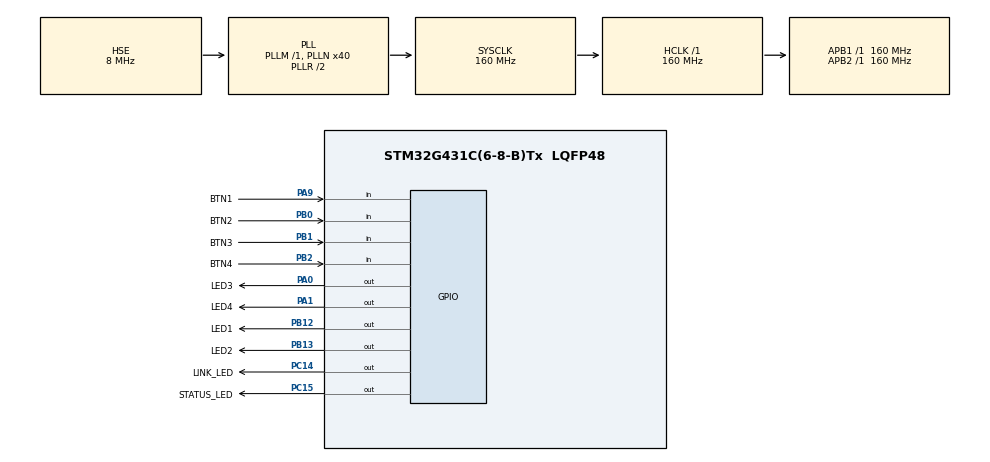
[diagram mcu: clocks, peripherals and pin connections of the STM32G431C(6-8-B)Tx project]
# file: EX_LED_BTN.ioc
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Mcu.Family=STM32G4
Mcu.Name=STM32G431C(6-8-B)Tx
Mcu.Package=LQFP48
NVIC.PriorityGroup=NVIC_PRIORITYGROUP_4
PA0.GPIO_Label=LED3
PA0.Signal=GPIO_Output
PA1.GPIO_Label=LED4
PA1.Signal=GPIO_Output
PA9.GPIO_Label=BTN1
PA9.GPIO_PuPd=GPIO_NOPULL
PA9.Signal=GPIO_Input
PB0.GPIO_Label=BTN2
PB0.GPIO_PuPd=GPIO_NOPULL
PB0.Signal=GPIO_Input
PB1.GPIO_Label=BTN3
PB1.GPIO_PuPd=GPIO_NOPULL
PB1.Signal=GPIO_Input
PB12.GPIO_Label=LED1
PB12.Signal=GPIO_Output
PB13.GPIO_Label=LED2
PB13.Signal=GPIO_Output
PB2.GPIO_Label=BTN4
PB2.GPIO_PuPd=GPIO_NOPULL
PB2.Signal=GPIO_Input
PC14-OSC32_IN.GPIO_Label=LINK_LED
PC14-OSC32_IN.Signal=GPIO_Output
PC15-OSC32_OUT.GPIO_Label=STATUS_LED
PC15-OSC32_OUT.Signal=GPIO_Output
PF0-OSC_IN.Mode=HSE-External-Oscillator
PF0-OSC_IN.Signal=RCC_OSC_IN
PF1-OSC_OUT.Mode=HSE-External-Oscillator
PF1-OSC_OUT.Signal=RCC_OSC_OUT
ProjectManager.HeapSize=0x200
ProjectManager.StackSize=0x400
ProjectManager.TargetToolchain=STM32CubeIDE
RCC.ADC12Freq_Value=160000000
RCC.AHBFreq_Value=160000000
RCC.APB1Freq_Value=160000000
RCC.APB1TimFreq_Value=160000000
RCC.APB2Freq_Value=160000000
RCC.APB2TimFreq_Value=160000000
RCC.CortexFreq_Value=160000000
RCC.EXTERNAL_CLOCK_VALUE=12288000
RCC.HCLKFreq_Value=160000000
RCC.HSE_VALUE=8000000
RCC.HSI48_VALUE=48000000
RCC.HSI_VALUE=16000000
RCC.LSE_VALUE=32768
RCC.PLLN=40
RCC.PLLSourceVirtual=RCC_PLLSOURCE_HSE
RCC.SYSCLKFreq_VALUE=160000000
RCC.SYSCLKSource=RCC_SYSCLKSOURCE_PLLCLK
RCC.USBFreq_Value=160000000
RCC.VCOOutputFreq_Value=320000000
VP_SYS_VS_DBSignals.Mode=DisableDeadBatterySignals
board=custom

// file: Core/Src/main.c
/* USER CODE BEGIN Header */
/**
  ******************************************************************************
  * @file           : main.c
  * @brief          : Main program body
  ******************************************************************************
  * @attention
  *
  * Copyright (c) 2025 STMicroelectronics.
  * All rights reserved.
  *
  * This software is licensed under terms that can be found in the LICENSE file
  * in the root directory of this software component.
  * If no LICENSE file comes with this software, it is provided AS-IS.
  *
  ******************************************************************************
  */
/* USER CODE END Header */
#include "main.h"

void SystemClock_Config(void);
static void MX_GPIO_Init(void);

/* USER CODE BEGIN 0 */

void ButtonLedTask(void)
{
  // 회로도를 참조하시면 해당 STATUS_LED_Pin 혹은  LINK_LED_Pin이 LOW로 떨어져야 LED 1,2가 켜집니다.
  // 버튼1 → LED1

  if (HAL_GPIO_ReadPin(BTN1_GPIO_Port, BTN1_Pin) == GPIO_PIN_RESET)
  {
	  HAL_GPIO_WritePin(STATUS_LED_GPIO_Port, STATUS_LED_Pin, GPIO_PIN_RESET);
  }
  else
  {
	  HAL_GPIO_WritePin(STATUS_LED_GPIO_Port, STATUS_LED_Pin, GPIO_PIN_SET);
  }

  // 버튼2 → LED2
  if (HAL_GPIO_ReadPin(BTN2_GPIO_Port, BTN2_Pin) == GPIO_PIN_RESET)
  {
	  HAL_GPIO_WritePin(LINK_LED_GPIO_Port, LINK_LED_Pin, GPIO_PIN_RESET);
  }
  else
  {
	  HAL_GPIO_WritePin(LINK_LED_GPIO_Port, LINK_LED_Pin, GPIO_PIN_SET);
  }

}

/* USER CODE END 0 */

int main(void)
{

  /* MCU Configuration--------------------------------------------------------*/

  /* Reset of all peripherals, Initializes the Flash interface and the Systick. */
  HAL_Init();

  /* Configure the system clock */
  SystemClock_Config();

  /* Initialize all configured peripherals */
  MX_GPIO_Init();

  /* Infinite loop */
  /* USER CODE BEGIN WHILE */
  while (1)
  {
	  // 버튼을 무한정 감시합니다!
	  ButtonLedTask();
    /* USER CODE END WHILE */

  }
}

void SystemClock_Config(void)
{
  RCC_OscInitTypeDef RCC_OscInitStruct = {0};
  RCC_ClkInitTypeDef RCC_ClkInitStruct = {0};

  /** Configure the main internal regulator output voltage
  */
  HAL_PWREx_ControlVoltageScaling(PWR_REGULATOR_VOLTAGE_SCALE1_BOOST);

  /** Initializes the RCC Oscillators according to the specified parameters
  * in the RCC_OscInitTypeDef structure.
  */
  RCC_OscInitStruct.OscillatorType = RCC_OSCILLATORTYPE_HSE;
  RCC_OscInitStruct.HSEState = RCC_HSE_ON;
  RCC_OscInitStruct.PLL.PLLState = RCC_PLL_ON;
  RCC_OscInitStruct.PLL.PLLSource = RCC_PLLSOURCE_HSE;
  RCC_OscInitStruct.PLL.PLLM = RCC_PLLM_DIV1;
  RCC_OscInitStruct.PLL.PLLN = 40;
  RCC_OscInitStruct.PLL.PLLP = RCC_PLLP_DIV2;
  RCC_OscInitStruct.PLL.PLLQ = RCC_PLLQ_DIV2;
  RCC_OscInitStruct.PLL.PLLR = RCC_PLLR_DIV2;
  if (HAL_RCC_OscConfig(&RCC_OscInitStruct) != HAL_OK)
  {
    Error_Handler();
  }

  /** Initializes the CPU, AHB and APB buses clocks
  */
  RCC_ClkInitStruct.ClockType = RCC_CLOCKTYPE_HCLK|RCC_CLOCKTYPE_SYSCLK
                              |RCC_CLOCKTYPE_PCLK1|RCC_CLOCKTYPE_PCLK2;
  RCC_ClkInitStruct.SYSCLKSource = RCC_SYSCLKSOURCE_PLLCLK;
  RCC_ClkInitStruct.AHBCLKDivider = RCC_SYSCLK_DIV1;
  RCC_ClkInitStruct.APB1CLKDivider = RCC_HCLK_DIV1;
  RCC_ClkInitStruct.APB2CLKDivider = RCC_HCLK_DIV1;

  if (HAL_RCC_ClockConfig(&RCC_ClkInitStruct, FLASH_LATENCY_4) != HAL_OK)
  {
    Error_Handler();
  }
}

static void MX_GPIO_Init(void)
{
  GPIO_InitTypeDef GPIO_InitStruct = {0};

  /* GPIO Ports Clock Enable */
  __HAL_RCC_GPIOC_CLK_ENABLE();
  __HAL_RCC_GPIOF_CLK_ENABLE();
  __HAL_RCC_GPIOA_CLK_ENABLE();
  __HAL_RCC_GPIOB_CLK_ENABLE();

  /*Configure GPIO pin Output Level */
  HAL_GPIO_WritePin(GPIOC, LINK_LED_Pin|STATUS_LED_Pin, GPIO_PIN_RESET);

  /*Configure GPIO pin Output Level */
  HAL_GPIO_WritePin(GPIOA, LED3_Pin|LED4_Pin, GPIO_PIN_RESET);

  /*Configure GPIO pin Output Level */
  HAL_GPIO_WritePin(GPIOB, LED1_Pin|LED2_Pin, GPIO_PIN_RESET);

  /*Configure GPIO pins : LINK_LED_Pin STATUS_LED_Pin */
  GPIO_InitStruct.Pin = LINK_LED_Pin|STATUS_LED_Pin;
  GPIO_InitStruct.Mode = GPIO_MODE_OUTPUT_PP;
  GPIO_InitStruct.Pull = GPIO_NOPULL;
  GPIO_InitStruct.Speed = GPIO_SPEED_FREQ_LOW;
  HAL_GPIO_Init(GPIOC, &GPIO_InitStruct);

  /*Configure GPIO pins : LED3_Pin LED4_Pin */
  GPIO_InitStruct.Pin = LED3_Pin|LED4_Pin;
  GPIO_InitStruct.Mode = GPIO_MODE_OUTPUT_PP;
  GPIO_InitStruct.Pull = GPIO_NOPULL;
  GPIO_InitStruct.Speed = GPIO_SPEED_FREQ_LOW;
  HAL_GPIO_Init(GPIOA, &GPIO_InitStruct);

  /*Configure GPIO pins : BTN2_Pin BTN3_Pin BTN4_Pin */
  GPIO_InitStruct.Pin = BTN2_Pin|BTN3_Pin|BTN4_Pin;
  GPIO_InitStruct.Mode = GPIO_MODE_INPUT;
  GPIO_InitStruct.Pull = GPIO_NOPULL;
  HAL_GPIO_Init(GPIOB, &GPIO_InitStruct);

  /*Configure GPIO pins : LED1_Pin LED2_Pin */
  GPIO_InitStruct.Pin = LED1_Pin|LED2_Pin;
  GPIO_InitStruct.Mode = GPIO_MODE_OUTPUT_PP;
  GPIO_InitStruct.Pull = GPIO_NOPULL;
  GPIO_InitStruct.Speed = GPIO_SPEED_FREQ_LOW;
  HAL_GPIO_Init(GPIOB, &GPIO_InitStruct);

  /*Configure GPIO pin : BTN1_Pin */
  GPIO_InitStruct.Pin = BTN1_Pin;
  GPIO_InitStruct.Mode = GPIO_MODE_INPUT;
  GPIO_InitStruct.Pull = GPIO_NOPULL;
  HAL_GPIO_Init(BTN1_GPIO_Port, &GPIO_InitStruct);

}

void Error_Handler(void)
{
  __disable_irq();
  while (1)
  {
  }
}
